VERSION ""
NS_ :

BS_:

BU_: DIM FSM

BO_ 400 DIM_Test1: 2 DIM
SG_ Ex1 : 0|1@1+ (1,0) [0|1] "" DEBUG
SG_ Ex2 : 1|12@1+ (1,0) [0|4095] "" DEBUG

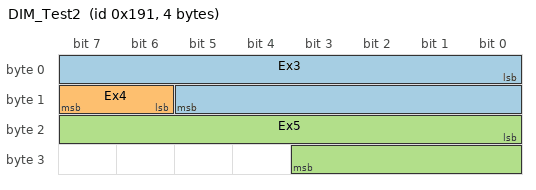
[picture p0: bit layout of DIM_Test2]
BO_ 401 DIM_Test2: 4 DIM
SG_ Ex3 : 0|14@1+ (0.1,0) [0|1000] "m/s^4" DEBUG
SG_ Ex4 : 14|2@1+ (1,0) [0|2] "" DEBUG
SG_ Ex5 : 16|12@1+ (0.1,-120) [-120|120] "deg" DEBUG

BO_ 410 DIM_AlertSet: 0 DIM
SG_ DIM_AlertSet : 0|0@1+ (1,0) [0|0] "" DEBUG

BO_ 411 DIM_AlertCleared: 0 DIM
SG_ DIM_AlertCleared : 0|0@1+ (1,0) [0|0] "" DEBUG

BO_ 300 FSM_Test1: 1 FSM
SG_ Ex1 : 0|1@1+ (1,0) [0|1] "" DEBUG

BO_ 310 FSM_AlertSet: 0 FSM
SG_ FSM_AlertSet : 0|0@1+ (1,0) [0|0] "" DEBUG

BO_ 311 FSM_AlertCleared: 0 FSM
SG_ FSM_AlertCleared : 0|0@1+ (1,0) [0|0] "" DEBUG

BA_DEF_  "BusType" STRING ;
BA_DEF_DEF_  "BusType" "CAN";

BA_ "GenSigStartValue" SG_ 400 Ex1 0;
BA_ "GenSigStartValue" SG_ 400 Ex2 0;
BA_ "GenSigStartValue" SG_ 401 Ex3 0;
BA_ "GenSigStartValue" SG_ 401 Ex4 0;
BA_ "GenSigStartValue" SG_ 401 Ex5 -120;
BA_ "GenSigStartValue" SG_ 410 DIM_AlertSet 0;
BA_ "GenSigStartValue" SG_ 411 DIM_AlertCleared 0;
BA_ "GenSigStartValue" SG_ 300 Ex1 0;
BA_ "GenSigStartValue" SG_ 310 FSM_AlertSet 0;
BA_ "GenSigStartValue" SG_ 311 FSM_AlertCleared 0;

BA_ "GenMsgCycleTime" BO_ 400  1000;
BA_ "GenMsgCycleTime" BO_ 401  10;
BA_ "GenMsgCycleTime" BO_ 300  1000;

VAL_ 401 Ex4 0 "CHOICE_0" 1 "CHOICE_1" 2 "CHOICE_2";
VAL_ 410 DIM_AlertSet 0 "NUM_DIM_ALERTS";
VAL_ 411 DIM_AlertCleared 0 "NUM_DIM_ALERTS";
VAL_ 310 FSM_AlertSet 0 "NUM_FSM_ALERTS";
VAL_ 311 FSM_AlertCleared 0 "NUM_FSM_ALERTS";
